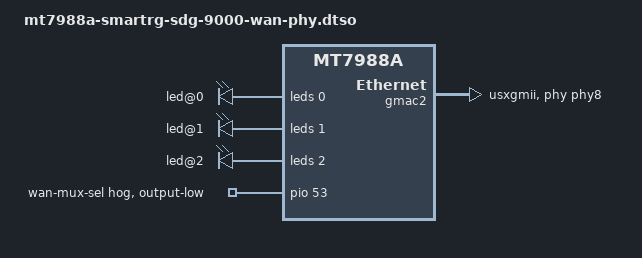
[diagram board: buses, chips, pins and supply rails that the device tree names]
// SPDX-License-Identifier: (GPL-2.0 OR MIT)

/dts-v1/;
/plugin/;

#include <dt-bindings/gpio/gpio.h>
#include <dt-bindings/leds/common.h>

/ {
	compatible = "smartrg,sdg-9000", "mediatek,mt7988a";
};

&gmac2 {
	phy-mode = "usxgmii";
	managed = "in-band-status";
	phy = <&phy8>;

	status = "okay";
};

&phy8 {
	leds {
		#address-cells = <1>;
		#size-cells = <0>;

		led@0 {
			reg = <0>;
			function = LED_FUNCTION_WAN;
			color = <LED_COLOR_ID_WHITE>;
		};

		led@1 {
			reg = <1>;
			function = LED_FUNCTION_WAN;
			color = <LED_COLOR_ID_ORANGE>;
		};

		led@2 {
			reg = <2>;
			function = LED_FUNCTION_WAN;
			color = <LED_COLOR_ID_GREEN>;
		};
	};
};

&pio {
	wan-mux-sel-hog {
		gpio-hog;
		gpios = <53 GPIO_ACTIVE_HIGH>;
		line-name = "wan-mux-sel";
		output-low; /* select CUX3410 */
	};
};
